# LRFDMDM register map
Vendor: Texas Instruments
Peripheral module from a debugger description file (folder CC27xxx7).
Registers are 32-bit, access per field, reset 0x0 unless marked. A register's access mark holds for its fields unless they carry their own. Offsets are as the file gives them; lines under a group give offsets from that group; [hi:lo] are bit positions; {n}, {i} and the like mark numbered series; 'fields as' and 'values as' point back to an identical list; <NAME> marks a mode.

## LRFDMDM (part 1 of 2)
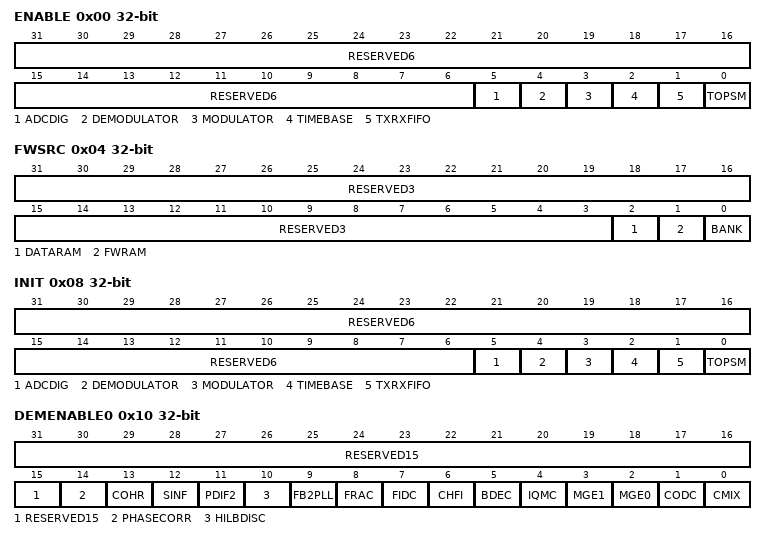
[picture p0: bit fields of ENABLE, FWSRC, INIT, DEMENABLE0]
0x00 ENABLE — Internal. Only to be used through TI provided API.
  [31:6] RESERVED6 ro — Internal. Only to be used through TI provided API.
  [5] ADCDIG rw — Internal. Only to be used through TI provided API.
    1=EN (Internal. Only to be used through TI provided API.); 0=DIS (Internal. Only to be used through TI provided API.)
  [4] DEMODULATOR rw — Internal. Only to be used through TI provided API.
    values as ADCDIG
  [3] MODULATOR rw — Internal. Only to be used through TI provided API.
    values as ADCDIG
  [2] TIMEBASE rw — Internal. Only to be used through TI provided API.
    values as ADCDIG
  [1] TXRXFIFO rw — Internal. Only to be used through TI provided API.
    values as ADCDIG
  [0] TOPSM rw — Internal. Only to be used through TI provided API.
    values as ADCDIG
0x04 FWSRC — Internal. Only to be used through TI provided API.
  [31:3] RESERVED3 ro — Internal. Only to be used through TI provided API.
  [2] DATARAM rw — Internal. Only to be used through TI provided API.
    1=S2RRAM (Internal. Only to be used through TI provided API.); 0=MDMRAM (Internal. Only to be used through TI provided API.)
  [1] FWRAM rw — Internal. Only to be used through TI provided API.
    values as DATARAM
  [0] BANK rw — Internal. Only to be used through TI provided API.
    1=ONE (Internal. Only to be used through TI provided API.); 0=ZERO (Internal. Only to be used through TI provided API.)
0x08 INIT — Internal. Only to be used through TI provided API.
  [31:6] RESERVED6 ro — Internal. Only to be used through TI provided API.
  [5] ADCDIG wo — Internal. Only to be used through TI provided API.
    1=RESET (Internal. Only to be used through TI provided API.); 0=NO_EFFECT (Internal. Only to be used through TI provided API.)
  [4] DEMODULATOR wo — Internal. Only to be used through TI provided API.
    values as ADCDIG
  [3] MODULATOR wo — Internal. Only to be used through TI provided API.
    values as ADCDIG
  [2] TIMEBASE wo — Internal. Only to be used through TI provided API.
    values as ADCDIG
  [1] TXRXFIFO wo — Internal. Only to be used through TI provided API.
    values as ADCDIG
  [0] TOPSM wo — Internal. Only to be used through TI provided API.
    values as ADCDIG
0x10 DEMENABLE0 — Internal. Only to be used through TI provided API.
  [31:15] RESERVED15 ro — Internal. Only to be used through TI provided API.
  [14] PHASECORR rw — Internal. Only to be used through TI provided API.
  [13] COHR rw — Internal. Only to be used through TI provided API.
  [12] SINF rw — Internal. Only to be used through TI provided API.
  [11] PDIF2 rw — Internal. Only to be used through TI provided API.
  [10] HILBDISC rw — Internal. Only to be used through TI provided API.
  [9] FB2PLL rw — Internal. Only to be used through TI provided API.
  [8] FRAC rw — Internal. Only to be used through TI provided API.
    values as ENABLE.ADCDIG
  [7] FIDC rw — Internal. Only to be used through TI provided API.
    values as ENABLE.ADCDIG
  [6] CHFI rw — Internal. Only to be used through TI provided API.
    values as ENABLE.ADCDIG
  [5] BDEC rw — Internal. Only to be used through TI provided API.
    values as ENABLE.ADCDIG
  [4] IQMC rw — Internal. Only to be used through TI provided API.
    values as ENABLE.ADCDIG
  [3] MGE1 rw — Internal. Only to be used through TI provided API.
    values as ENABLE.ADCDIG
  [2] MGE0 rw — Internal. Only to be used through TI provided API.
    values as ENABLE.ADCDIG
  [1] CODC rw — Internal. Only to be used through TI provided API.
    values as ENABLE.ADCDIG
  [0] CMIX rw — Internal. Only to be used through TI provided API.
    values as ENABLE.ADCDIG
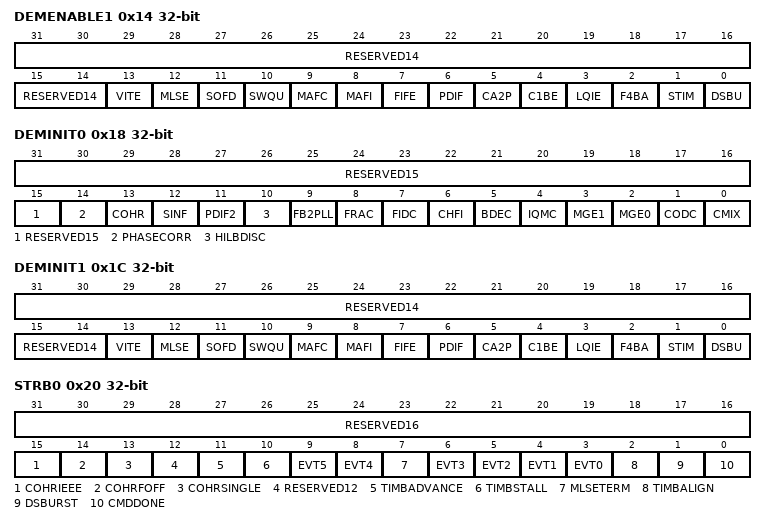
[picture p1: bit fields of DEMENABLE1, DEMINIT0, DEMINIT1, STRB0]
0x14 DEMENABLE1 — Internal. Only to be used through TI provided API.
  [31:14] RESERVED14 ro — Internal. Only to be used through TI provided API.
  [13] VITE rw — Internal. Only to be used through TI provided API.
    values as ENABLE.ADCDIG
  [12] MLSE rw — Internal. Only to be used through TI provided API.
    values as ENABLE.ADCDIG
  [11] SOFD rw — Internal. Only to be used through TI provided API.
    values as ENABLE.ADCDIG
  [10] SWQU rw — Internal. Only to be used through TI provided API.
    values as ENABLE.ADCDIG
  [9] MAFC rw — Internal. Only to be used through TI provided API.
    values as ENABLE.ADCDIG
  [8] MAFI rw — Internal. Only to be used through TI provided API.
    values as ENABLE.ADCDIG
  [7] FIFE rw — Internal. Only to be used through TI provided API.
    values as ENABLE.ADCDIG
  [6] PDIF rw — Internal. Only to be used through TI provided API.
    values as ENABLE.ADCDIG
  [5] CA2P rw — Internal. Only to be used through TI provided API.
    values as ENABLE.ADCDIG
  [4] C1BE rw — Internal. Only to be used through TI provided API.
    values as ENABLE.ADCDIG
  [3] LQIE rw — Internal. Only to be used through TI provided API.
    values as ENABLE.ADCDIG
  [2] F4BA rw — Internal. Only to be used through TI provided API.
    values as ENABLE.ADCDIG
  [1] STIM rw — Internal. Only to be used through TI provided API.
    values as ENABLE.ADCDIG
  [0] DSBU rw — Internal. Only to be used through TI provided API.
    values as ENABLE.ADCDIG
0x18 DEMINIT0 — Internal. Only to be used through TI provided API.
  [31:15] RESERVED15 ro — Internal. Only to be used through TI provided API.
  [14] PHASECORR wo — Internal. Only to be used through TI provided API.
  [13] COHR wo — Internal. Only to be used through TI provided API.
  [12] SINF wo — Internal. Only to be used through TI provided API.
  [11] PDIF2 wo — Internal. Only to be used through TI provided API.
  [10] HILBDISC wo — Internal. Only to be used through TI provided API.
  [9] FB2PLL wo — Internal. Only to be used through TI provided API.
  [8] FRAC wo — Internal. Only to be used through TI provided API.
    values as INIT.ADCDIG
  [7] FIDC wo — Internal. Only to be used through TI provided API.
    values as INIT.ADCDIG
  [6] CHFI wo — Internal. Only to be used through TI provided API.
    values as INIT.ADCDIG
  [5] BDEC wo — Internal. Only to be used through TI provided API.
    values as INIT.ADCDIG
  [4] IQMC wo — Internal. Only to be used through TI provided API.
    values as INIT.ADCDIG
  [3] MGE1 wo — Internal. Only to be used through TI provided API.
    values as INIT.ADCDIG
  [2] MGE0 wo — Internal. Only to be used through TI provided API.
    values as INIT.ADCDIG
  [1] CODC wo — Internal. Only to be used through TI provided API.
    values as INIT.ADCDIG
  [0] CMIX wo — Internal. Only to be used through TI provided API.
    values as INIT.ADCDIG
0x1C DEMINIT1 — Internal. Only to be used through TI provided API.
  [31:14] RESERVED14 ro — Internal. Only to be used through TI provided API.
  [13] VITE wo — Internal. Only to be used through TI provided API.
    values as INIT.ADCDIG
  [12] MLSE wo — Internal. Only to be used through TI provided API.
    values as INIT.ADCDIG
  [11] SOFD wo — Internal. Only to be used through TI provided API.
    values as INIT.ADCDIG
  [10] SWQU wo — Internal. Only to be used through TI provided API.
    values as INIT.ADCDIG
  [9] MAFC wo — Internal. Only to be used through TI provided API.
    values as INIT.ADCDIG
  [8] MAFI wo — Internal. Only to be used through TI provided API.
    values as INIT.ADCDIG
  [7] FIFE wo — Internal. Only to be used through TI provided API.
    values as INIT.ADCDIG
  [6] PDIF wo — Internal. Only to be used through TI provided API.
    values as INIT.ADCDIG
  [5] CA2P wo — Internal. Only to be used through TI provided API.
    values as INIT.ADCDIG
  [4] C1BE wo — Internal. Only to be used through TI provided API.
    values as INIT.ADCDIG
  [3] LQIE wo — Internal. Only to be used through TI provided API.
    values as INIT.ADCDIG
  [2] F4BA wo — Internal. Only to be used through TI provided API.
    values as INIT.ADCDIG
  [1] STIM wo — Internal. Only to be used through TI provided API.
    values as INIT.ADCDIG
  [0] DSBU wo — Internal. Only to be used through TI provided API.
    values as INIT.ADCDIG
0x20 STRB0 — Internal. Only to be used through TI provided API.
  [31:16] RESERVED16 ro — Internal. Only to be used through TI provided API.
  [15] COHRIEEE wo — Internal. Only to be used through TI provided API.
  [14] COHRFOFF wo — Internal. Only to be used through TI provided API.
  [13] COHRSINGLE wo — Internal. Only to be used through TI provided API.
  [12] RESERVED12 ro — Internal. Only to be used through TI provided API.
  [11] TIMBADVANCE wo — Internal. Only to be used through TI provided API.
    1=ON (Internal. Only to be used through TI provided API.); 0=NO_EFFECT (Internal. Only to be used through TI provided API.)
  [10] TIMBSTALL wo — Internal. Only to be used through TI provided API.
    values as TIMBADVANCE
  [9] EVT5 wo — Internal. Only to be used through TI provided API.
    values as FWSRC.BANK
  [8] EVT4 wo — Internal. Only to be used through TI provided API.
    values as FWSRC.BANK
  [7] MLSETERM wo — Internal. Only to be used through TI provided API.
    1=ON (Internal. Only to be used through TI provided API.); 0=OFF (Internal. Only to be used through TI provided API.)
  [n+3] EVT{n} wo (n=0..3) — Internal. Only to be used through TI provided API.
    values as FWSRC.BANK
  [2] TIMBALIGN wo — Internal. Only to be used through TI provided API.
    values as TIMBADVANCE
  [1] DSBURST wo — Internal. Only to be used through TI provided API.
    1=RESTART (Internal. Only to be used through TI provided API.); 0=NO_EFFECT (Internal. Only to be used through TI provided API.)
  [0] CMDDONE wo — Internal. Only to be used through TI provided API.
    1=YES (Internal. Only to be used through TI provided API.); 0=NO (Internal. Only to be used through TI provided API.)
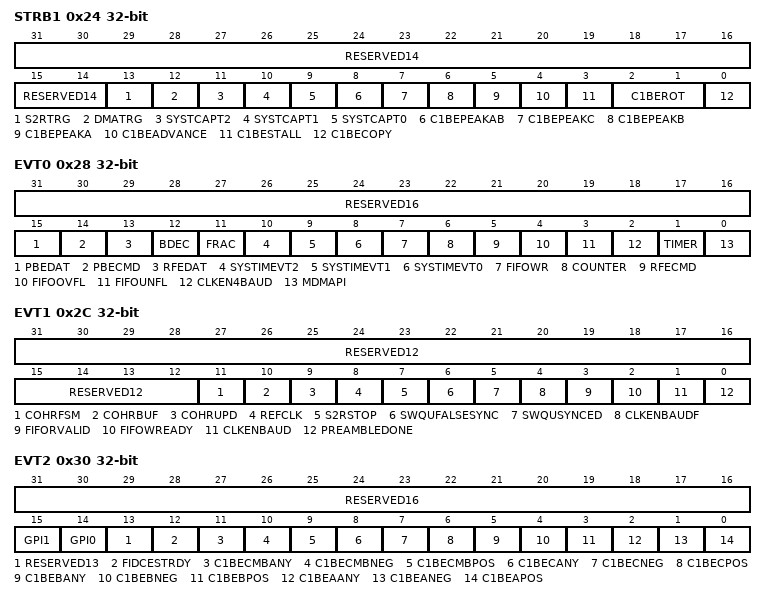
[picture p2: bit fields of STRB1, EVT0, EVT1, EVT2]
0x24 STRB1 — Internal. Only to be used through TI provided API.
  [31:14] RESERVED14 ro — Internal. Only to be used through TI provided API.
  [13] S2RTRG wo — Internal. Only to be used through TI provided API.
    values as FWSRC.BANK
  [12] DMATRG wo — Internal. Only to be used through TI provided API.
    values as FWSRC.BANK
  [11] SYSTCAPT2 wo — Internal. Only to be used through TI provided API.
    values as FWSRC.BANK
  [10] SYSTCAPT1 wo — Internal. Only to be used through TI provided API.
    values as FWSRC.BANK
  [9] SYSTCAPT0 wo — Internal. Only to be used through TI provided API.
    values as FWSRC.BANK
  [8] C1BEPEAKAB wo — Internal. Only to be used through TI provided API.
    values as FWSRC.BANK
  [7] C1BEPEAKC wo — Internal. Only to be used through TI provided API.
    values as FWSRC.BANK
  [6] C1BEPEAKB wo — Internal. Only to be used through TI provided API.
    values as FWSRC.BANK
  [5] C1BEPEAKA wo — Internal. Only to be used through TI provided API.
    values as FWSRC.BANK
  [4] C1BEADVANCE wo — Internal. Only to be used through TI provided API.
    values as FWSRC.BANK
  [3] C1BESTALL wo — Internal. Only to be used through TI provided API.
    values as FWSRC.BANK
  [2:1] C1BEROT wo — Internal. Only to be used through TI provided API.
    3=ROT16R (Internal. Only to be used through TI provided API.); 2=ROT1L (Internal. Only to be used through TI provided API.); 1=ROT1R (Internal. Only to be used through TI provided API.); 0=ROT0 (Internal. Only to be used through TI provided API.)
  [0] C1BECOPY wo — Internal. Only to be used through TI provided API.
    values as FWSRC.BANK
0x28 EVT0 ro — Internal. Only to be used through TI provided API.
  [31:16] RESERVED16 — Internal. Only to be used through TI provided API.
  [15] PBEDAT — Internal. Only to be used through TI provided API.
    values as FWSRC.BANK
  [14] PBECMD — Internal. Only to be used through TI provided API.
    values as FWSRC.BANK
  [13] RFEDAT — Internal. Only to be used through TI provided API.
    values as FWSRC.BANK
  [12] BDEC — Internal. Only to be used through TI provided API.
    values as FWSRC.BANK
  [11] FRAC — Internal. Only to be used through TI provided API.
    values as FWSRC.BANK
  [10] SYSTIMEVT2 — Internal. Only to be used through TI provided API.
    values as FWSRC.BANK
  [9] SYSTIMEVT1 — Internal. Only to be used through TI provided API.
    values as FWSRC.BANK
  [8] SYSTIMEVT0 — Internal. Only to be used through TI provided API.
    values as FWSRC.BANK
  [7] FIFOWR — Internal. Only to be used through TI provided API.
    values as FWSRC.BANK
  [6] COUNTER — Internal. Only to be used through TI provided API.
    values as FWSRC.BANK
  [5] RFECMD — Internal. Only to be used through TI provided API.
    values as FWSRC.BANK
  [4] FIFOOVFL — Internal. Only to be used through TI provided API.
    values as FWSRC.BANK
  [3] FIFOUNFL — Internal. Only to be used through TI provided API.
    values as FWSRC.BANK
  [2] CLKEN4BAUD — Internal. Only to be used through TI provided API.
    values as FWSRC.BANK
  [1] TIMER — Internal. Only to be used through TI provided API.
    values as FWSRC.BANK
  [0] MDMAPI — Internal. Only to be used through TI provided API.
    values as FWSRC.BANK
0x2C EVT1 ro — Internal. Only to be used through TI provided API.
  [31:12] RESERVED12 — Internal. Only to be used through TI provided API.
  [11] COHRFSM — Internal. Only to be used through TI provided API.
  [10] COHRBUF — Internal. Only to be used through TI provided API.
  [9] COHRUPD — Internal. Only to be used through TI provided API.
  [8] REFCLK — Internal. Only to be used through TI provided API.
    values as FWSRC.BANK
  [7] S2RSTOP — Internal. Only to be used through TI provided API.
    values as FWSRC.BANK
  [6] SWQUFALSESYNC — Internal. Only to be used through TI provided API.
    values as FWSRC.BANK
  [5] SWQUSYNCED — Internal. Only to be used through TI provided API.
    values as FWSRC.BANK
  [4] CLKENBAUDF — Internal. Only to be used through TI provided API.
    values as FWSRC.BANK
  [3] FIFORVALID — Internal. Only to be used through TI provided API.
    values as FWSRC.BANK
  [2] FIFOWREADY — Internal. Only to be used through TI provided API.
    values as FWSRC.BANK
  [1] CLKENBAUD — Internal. Only to be used through TI provided API.
    values as FWSRC.BANK
  [0] PREAMBLEDONE — Internal. Only to be used through TI provided API.
    values as FWSRC.BANK
0x30 EVT2 ro — Internal. Only to be used through TI provided API.
  [31:16] RESERVED16 — Internal. Only to be used through TI provided API.
  [15] GPI1 — Internal. Only to be used through TI provided API.
    values as FWSRC.BANK
  [14] GPI0 — Internal. Only to be used through TI provided API.
    values as FWSRC.BANK
  [13] RESERVED13 — Internal. Only to be used through TI provided API.
  [12] FIDCESTRDY — Internal. Only to be used through TI provided API.
    values as FWSRC.BANK
  [11] C1BECMBANY — Internal. Only to be used through TI provided API.
    values as FWSRC.BANK
  [10] C1BECMBNEG — Internal. Only to be used through TI provided API.
    values as FWSRC.BANK
  [9] C1BECMBPOS — Internal. Only to be used through TI provided API.
    values as FWSRC.BANK
  [8] C1BECANY — Internal. Only to be used through TI provided API.
    values as FWSRC.BANK
  [7] C1BECNEG — Internal. Only to be used through TI provided API.
    values as FWSRC.BANK
  [6] C1BECPOS — Internal. Only to be used through TI provided API.
    values as FWSRC.BANK
  [5] C1BEBANY — Internal. Only to be used through TI provided API.
    values as FWSRC.BANK
  [4] C1BEBNEG — Internal. Only to be used through TI provided API.
    values as FWSRC.BANK
  [3] C1BEBPOS — Internal. Only to be used through TI provided API.
    values as FWSRC.BANK
  [2] C1BEAANY — Internal. Only to be used through TI provided API.
    values as FWSRC.BANK
  [1] C1BEANEG — Internal. Only to be used through TI provided API.
    values as FWSRC.BANK
  [0] C1BEAPOS — Internal. Only to be used through TI provided API.
    values as FWSRC.BANK
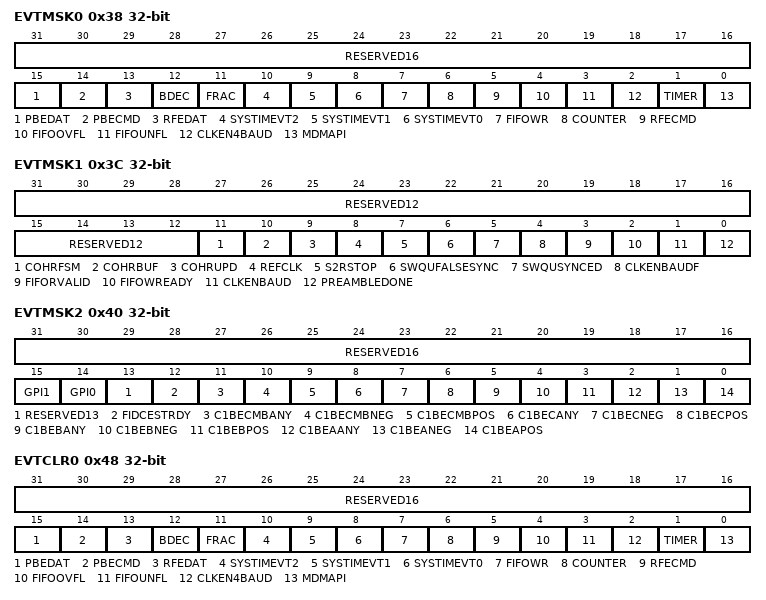
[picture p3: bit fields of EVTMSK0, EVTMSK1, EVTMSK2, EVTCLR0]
0x38 EVTMSK0 — Internal. Only to be used through TI provided API.
  [31:16] RESERVED16 ro — Internal. Only to be used through TI provided API.
  [15] PBEDAT rw — Internal. Only to be used through TI provided API.
    values as ENABLE.ADCDIG
  [14] PBECMD rw — Internal. Only to be used through TI provided API.
    values as ENABLE.ADCDIG
  [13] RFEDAT rw — Internal. Only to be used through TI provided API.
    values as ENABLE.ADCDIG
  [12] BDEC rw — Internal. Only to be used through TI provided API.
    values as ENABLE.ADCDIG
  [11] FRAC rw — Internal. Only to be used through TI provided API.
    values as ENABLE.ADCDIG
  [10] SYSTIMEVT2 rw — Internal. Only to be used through TI provided API.
    values as ENABLE.ADCDIG
  [9] SYSTIMEVT1 rw — Internal. Only to be used through TI provided API.
    values as ENABLE.ADCDIG
  [8] SYSTIMEVT0 rw — Internal. Only to be used through TI provided API.
    values as ENABLE.ADCDIG
  [7] FIFOWR rw — Internal. Only to be used through TI provided API.
    values as ENABLE.ADCDIG
  [6] COUNTER rw — Internal. Only to be used through TI provided API.
    values as ENABLE.ADCDIG
  [5] RFECMD rw — Internal. Only to be used through TI provided API.
    values as ENABLE.ADCDIG
  [4] FIFOOVFL rw — Internal. Only to be used through TI provided API.
    values as ENABLE.ADCDIG
  [3] FIFOUNFL rw — Internal. Only to be used through TI provided API.
    values as ENABLE.ADCDIG
  [2] CLKEN4BAUD rw — Internal. Only to be used through TI provided API.
    values as ENABLE.ADCDIG
  [1] TIMER rw — Internal. Only to be used through TI provided API.
    values as ENABLE.ADCDIG
  [0] MDMAPI rw — Internal. Only to be used through TI provided API.
    values as ENABLE.ADCDIG
0x3C EVTMSK1 — Internal. Only to be used through TI provided API.
  [31:12] RESERVED12 ro — Internal. Only to be used through TI provided API.
  [11] COHRFSM rw — Internal. Only to be used through TI provided API.
  [10] COHRBUF rw — Internal. Only to be used through TI provided API.
  [9] COHRUPD rw — Internal. Only to be used through TI provided API.
  [8] REFCLK rw — Internal. Only to be used through TI provided API.
    values as ENABLE.ADCDIG
  [7] S2RSTOP rw — Internal. Only to be used through TI provided API.
    values as ENABLE.ADCDIG
  [6] SWQUFALSESYNC rw — Internal. Only to be used through TI provided API.
    values as ENABLE.ADCDIG
  [5] SWQUSYNCED rw — Internal. Only to be used through TI provided API.
    values as ENABLE.ADCDIG
  [4] CLKENBAUDF rw — Internal. Only to be used through TI provided API.
    values as ENABLE.ADCDIG
  [3] FIFORVALID rw — Internal. Only to be used through TI provided API.
    values as ENABLE.ADCDIG
  [2] FIFOWREADY rw — Internal. Only to be used through TI provided API.
    values as ENABLE.ADCDIG
  [1] CLKENBAUD rw — Internal. Only to be used through TI provided API.
    values as ENABLE.ADCDIG
  [0] PREAMBLEDONE rw — Internal. Only to be used through TI provided API.
    values as ENABLE.ADCDIG
0x40 EVTMSK2 — Internal. Only to be used through TI provided API.
  [31:16] RESERVED16 ro — Internal. Only to be used through TI provided API.
  [15] GPI1 rw — Internal. Only to be used through TI provided API.
    values as ENABLE.ADCDIG
  [14] GPI0 rw — Internal. Only to be used through TI provided API.
    values as ENABLE.ADCDIG
  [13] RESERVED13 ro — Internal. Only to be used through TI provided API.
  [12] FIDCESTRDY rw — Internal. Only to be used through TI provided API.
    values as ENABLE.ADCDIG
  [11] C1BECMBANY rw — Internal. Only to be used through TI provided API.
    values as ENABLE.ADCDIG
  [10] C1BECMBNEG rw — Internal. Only to be used through TI provided API.
    values as ENABLE.ADCDIG
  [9] C1BECMBPOS rw — Internal. Only to be used through TI provided API.
    values as ENABLE.ADCDIG
  [8] C1BECANY rw — Internal. Only to be used through TI provided API.
    values as ENABLE.ADCDIG
  [7] C1BECNEG rw — Internal. Only to be used through TI provided API.
    values as ENABLE.ADCDIG
  [6] C1BECPOS rw — Internal. Only to be used through TI provided API.
    values as ENABLE.ADCDIG
  [5] C1BEBANY rw — Internal. Only to be used through TI provided API.
    values as ENABLE.ADCDIG
  [4] C1BEBNEG rw — Internal. Only to be used through TI provided API.
    values as ENABLE.ADCDIG
  [3] C1BEBPOS rw — Internal. Only to be used through TI provided API.
    values as ENABLE.ADCDIG
  [2] C1BEAANY rw — Internal. Only to be used through TI provided API.
    values as ENABLE.ADCDIG
  [1] C1BEANEG rw — Internal. Only to be used through TI provided API.
    values as ENABLE.ADCDIG
  [0] C1BEAPOS rw — Internal. Only to be used through TI provided API.
    values as ENABLE.ADCDIG
0x48 EVTCLR0 — Internal. Only to be used through TI provided API.
  [31:16] RESERVED16 ro — Internal. Only to be used through TI provided API.
  [15] PBEDAT wo — Internal. Only to be used through TI provided API.
    1=CLEAR (Internal. Only to be used through TI provided API.); 0=RETAIN (Internal. Only to be used through TI provided API.)
  [14] PBECMD wo — Internal. Only to be used through TI provided API.
    values as PBEDAT
  [13] RFEDAT wo — Internal. Only to be used through TI provided API.
    values as PBEDAT
  [12] BDEC wo — Internal. Only to be used through TI provided API.
    values as PBEDAT
  [11] FRAC wo — Internal. Only to be used through TI provided API.
    values as PBEDAT
  [10] SYSTIMEVT2 wo — Internal. Only to be used through TI provided API.
    values as PBEDAT
  [9] SYSTIMEVT1 wo — Internal. Only to be used through TI provided API.
    values as PBEDAT
  [8] SYSTIMEVT0 wo — Internal. Only to be used through TI provided API.
    values as PBEDAT
  [7] FIFOWR wo — Internal. Only to be used through TI provided API.
    values as PBEDAT
  [6] COUNTER wo — Internal. Only to be used through TI provided API.
    values as PBEDAT
  [5] RFECMD wo — Internal. Only to be used through TI provided API.
    values as PBEDAT
  [4] FIFOOVFL wo — Internal. Only to be used through TI provided API.
    values as PBEDAT
  [3] FIFOUNFL wo — Internal. Only to be used through TI provided API.
    values as PBEDAT
  [2] CLKEN4BAUD wo — Internal. Only to be used through TI provided API.
    values as PBEDAT
  [1] TIMER wo — Internal. Only to be used through TI provided API.
    values as PBEDAT
  [0] MDMAPI wo — Internal. Only to be used through TI provided API.
    values as PBEDAT
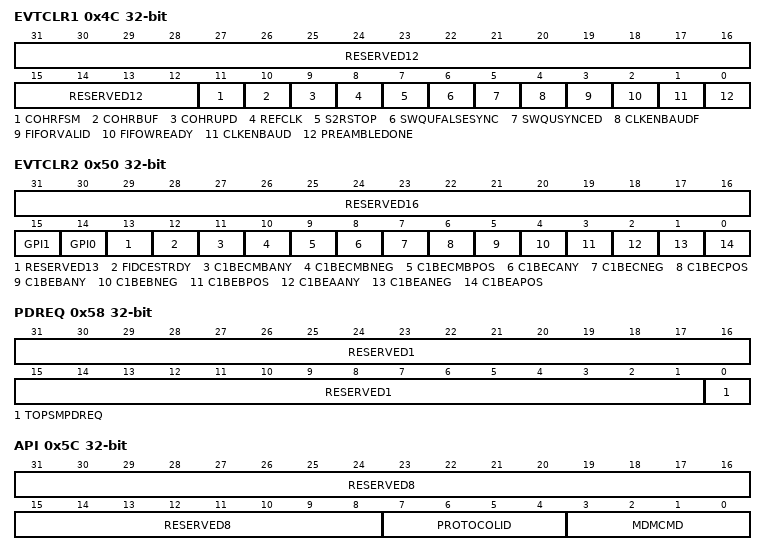
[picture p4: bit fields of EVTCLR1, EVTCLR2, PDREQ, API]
0x4C EVTCLR1 — Internal. Only to be used through TI provided API.
  [31:12] RESERVED12 ro — Internal. Only to be used through TI provided API.
  [11] COHRFSM wo — Internal. Only to be used through TI provided API.
  [10] COHRBUF wo — Internal. Only to be used through TI provided API.
  [9] COHRUPD wo — Internal. Only to be used through TI provided API.
  [8] REFCLK wo — Internal. Only to be used through TI provided API.
    values as EVTCLR0.PBEDAT
  [7] S2RSTOP wo — Internal. Only to be used through TI provided API.
    values as EVTCLR0.PBEDAT
  [6] SWQUFALSESYNC wo — Internal. Only to be used through TI provided API.
    values as EVTCLR0.PBEDAT
  [5] SWQUSYNCED wo — Internal. Only to be used through TI provided API.
    values as EVTCLR0.PBEDAT
  [4] CLKENBAUDF wo — Internal. Only to be used through TI provided API.
    values as EVTCLR0.PBEDAT
  [3] FIFORVALID wo — Internal. Only to be used through TI provided API.
    values as EVTCLR0.PBEDAT
  [2] FIFOWREADY wo — Internal. Only to be used through TI provided API.
    values as EVTCLR0.PBEDAT
  [1] CLKENBAUD wo — Internal. Only to be used through TI provided API.
    values as EVTCLR0.PBEDAT
  [0] PREAMBLEDONE wo — Internal. Only to be used through TI provided API.
    values as EVTCLR0.PBEDAT
0x50 EVTCLR2 — Internal. Only to be used through TI provided API.
  [31:16] RESERVED16 ro — Internal. Only to be used through TI provided API.
  [15] GPI1 wo — Internal. Only to be used through TI provided API.
    values as EVTCLR0.PBEDAT
  [14] GPI0 wo — Internal. Only to be used through TI provided API.
    values as EVTCLR0.PBEDAT
  [13] RESERVED13 ro — Internal. Only to be used through TI provided API.
  [12] FIDCESTRDY wo — Internal. Only to be used through TI provided API.
    values as EVTCLR0.PBEDAT
  [11] C1BECMBANY wo — Internal. Only to be used through TI provided API.
    values as EVTCLR0.PBEDAT
  [10] C1BECMBNEG wo — Internal. Only to be used through TI provided API.
    values as EVTCLR0.PBEDAT
  [9] C1BECMBPOS wo — Internal. Only to be used through TI provided API.
    values as EVTCLR0.PBEDAT
  [8] C1BECANY wo — Internal. Only to be used through TI provided API.
    values as EVTCLR0.PBEDAT
  [7] C1BECNEG wo — Internal. Only to be used through TI provided API.
    values as EVTCLR0.PBEDAT
  [6] C1BECPOS wo — Internal. Only to be used through TI provided API.
    values as EVTCLR0.PBEDAT
  [5] C1BEBANY wo — Internal. Only to be used through TI provided API.
    values as EVTCLR0.PBEDAT
  [4] C1BEBNEG wo — Internal. Only to be used through TI provided API.
    values as EVTCLR0.PBEDAT
  [3] C1BEBPOS wo — Internal. Only to be used through TI provided API.
    values as EVTCLR0.PBEDAT
  [2] C1BEAANY wo — Internal. Only to be used through TI provided API.
    values as EVTCLR0.PBEDAT
  [1] C1BEANEG wo — Internal. Only to be used through TI provided API.
    values as EVTCLR0.PBEDAT
  [0] C1BEAPOS wo — Internal. Only to be used through TI provided API.
    values as EVTCLR0.PBEDAT
0x58 PDREQ — Internal. Only to be used through TI provided API.
  [31:1] RESERVED1 ro — Internal. Only to be used through TI provided API.
  [0] TOPSMPDREQ rw — Internal. Only to be used through TI provided API.
    values as STRB0.MLSETERM
0x5C API ro — Internal. Only to be used through TI provided API.
  [31:8] RESERVED8 — Internal. Only to be used through TI provided API.
  [7:4] PROTOCOLID — Internal. Only to be used through TI provided API.
    15=ALLONES (Internal. Only to be used through TI provided API.); 0=ALLZEROS (Internal. Only to be used through TI provided API.)
  [3:0] MDMCMD — Internal. Only to be used through TI provided API.
    values as PROTOCOLID
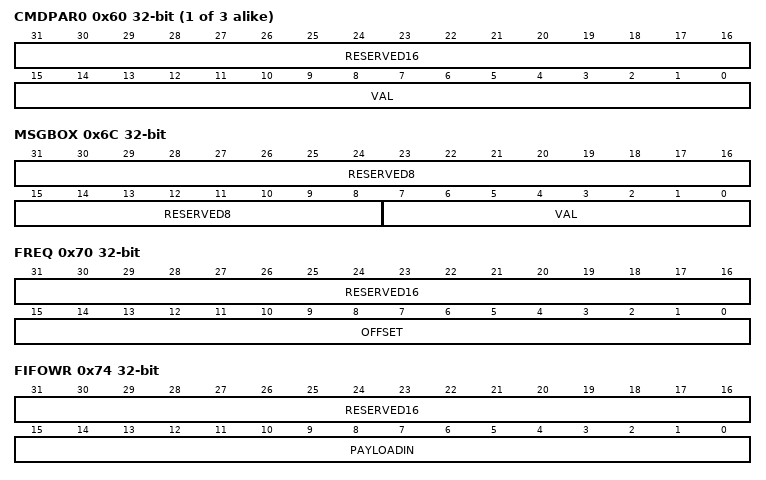
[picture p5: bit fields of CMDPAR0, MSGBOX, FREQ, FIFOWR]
{0x60+4i} CMDPAR{i} ro (i=0..2) — Internal. Only to be used through TI provided API.
  [31:16] RESERVED16 — Internal. Only to be used through TI provided API.
  [15:0] VAL — Internal. Only to be used through TI provided API.
    0xFFFF=ALLONES (Internal. Only to be used through TI provided API.); 0=ALLZEROS (Internal. Only to be used through TI provided API.)
0x6C MSGBOX — Internal. Only to be used through TI provided API.
  [31:8] RESERVED8 ro — Internal. Only to be used through TI provided API.
  [7:0] VAL rw — Internal. Only to be used through TI provided API.
    255=ALLONES (Internal. Only to be used through TI provided API.); 0=ALLZEROS (Internal. Only to be used through TI provided API.)
0x70 FREQ — Internal. Only to be used through TI provided API.
  [31:16] RESERVED16 ro — Internal. Only to be used through TI provided API.
  [15:0] OFFSET rw — Internal. Only to be used through TI provided API.
    values as CMDPAR0.VAL
0x74 FIFOWR — Internal. Only to be used through TI provided API.
  [31:16] RESERVED16 ro — Internal. Only to be used through TI provided API.
  [15:0] PAYLOADIN rw — Internal. Only to be used through TI provided API.
    values as CMDPAR0.VAL
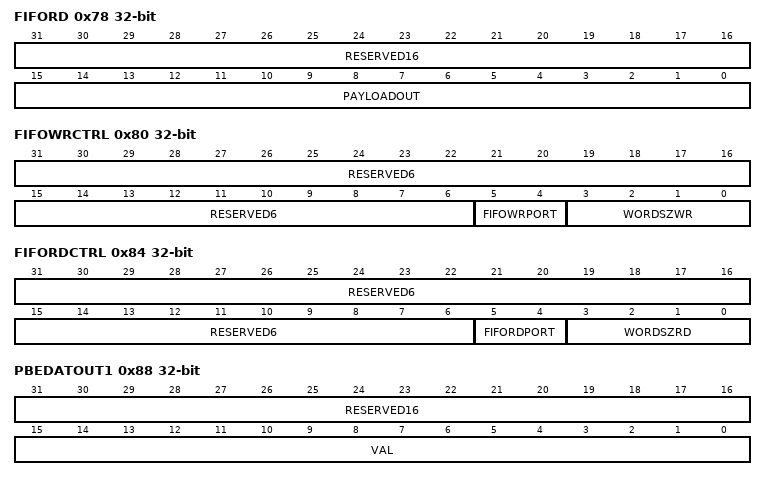
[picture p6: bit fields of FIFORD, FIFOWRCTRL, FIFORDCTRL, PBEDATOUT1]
0x78 FIFORD ro — Internal. Only to be used through TI provided API.
  [31:16] RESERVED16 — Internal. Only to be used through TI provided API.
  [15:0] PAYLOADOUT — Internal. Only to be used through TI provided API.
    values as CMDPAR0.VAL
0x80 FIFOWRCTRL — Internal. Only to be used through TI provided API.
  [31:6] RESERVED6 ro — Internal. Only to be used through TI provided API.
  [5:4] FIFOWRPORT rw — Internal. Only to be used through TI provided API.
    2=PBE (Internal. Only to be used through TI provided API.); 1=MODEM (Internal. Only to be used through TI provided API.); 0=MDMFIFOWR (Internal. Only to be used through TI provided API.)
  [3:0] WORDSZWR rw — Internal. Only to be used through TI provided API.
    {v}=BITS{v+1} (Internal. Only to be used through TI provided API.) (v=0..15)
0x84 FIFORDCTRL — Internal. Only to be used through TI provided API.
  [31:6] RESERVED6 ro — Internal. Only to be used through TI provided API.
  [5:4] FIFORDPORT rw — Internal. Only to be used through TI provided API.
    2=PBE (Internal. Only to be used through TI provided API.); 1=MODEM (Internal. Only to be used through TI provided API.); 0=MDMFIFORD (Internal. Only to be used through TI provided API.)
  [3:0] WORDSZRD rw — Internal. Only to be used through TI provided API.
    values as FIFOWRCTRL.WORDSZWR
0x88 PBEDATOUT1 — Internal. Only to be used through TI provided API.
  [31:16] RESERVED16 ro — Internal. Only to be used through TI provided API.
  [15:0] VAL rw — Internal. Only to be used through TI provided API.
    values as CMDPAR0.VAL
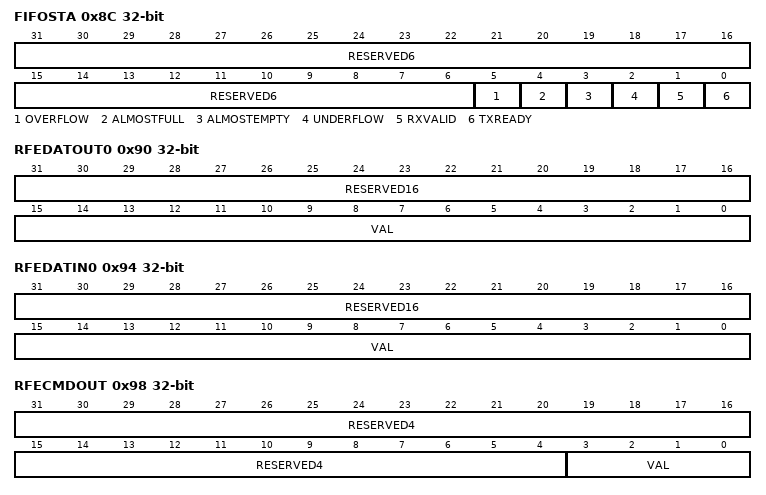
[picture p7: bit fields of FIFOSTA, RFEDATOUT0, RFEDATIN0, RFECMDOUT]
0x8C FIFOSTA ro — Internal. Only to be used through TI provided API.
  [31:6] RESERVED6 — Internal. Only to be used through TI provided API.
  [5] OVERFLOW — Internal. Only to be used through TI provided API.
    values as FWSRC.BANK
  [4] ALMOSTFULL — Internal. Only to be used through TI provided API.
    values as FWSRC.BANK
  [3] ALMOSTEMPTY — Internal. Only to be used through TI provided API.
    values as FWSRC.BANK
  [2] UNDERFLOW — Internal. Only to be used through TI provided API.
    values as FWSRC.BANK
  [1] RXVALID — Internal. Only to be used through TI provided API.
    values as FWSRC.BANK
  [0] TXREADY — Internal. Only to be used through TI provided API.
    values as FWSRC.BANK
0x90 RFEDATOUT0 — Internal. Only to be used through TI provided API.
  fields as PBEDATOUT1
0x94 RFEDATIN0 ro — Internal. Only to be used through TI provided API.
  fields as CMDPAR0
0x98 RFECMDOUT — Internal. Only to be used through TI provided API.
  [31:4] RESERVED4 ro — Internal. Only to be used through TI provided API.
  [3:0] VAL rw — Internal. Only to be used through TI provided API.
    values as API.PROTOCOLID
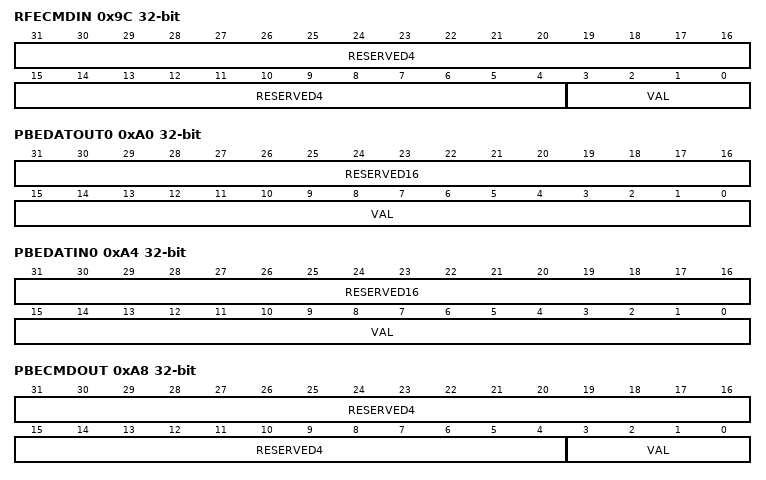
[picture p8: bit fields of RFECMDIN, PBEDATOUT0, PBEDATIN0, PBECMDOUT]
0x9C RFECMDIN ro — Internal. Only to be used through TI provided API.
  [31:4] RESERVED4 — Internal. Only to be used through TI provided API.
  [3:0] VAL — Internal. Only to be used through TI provided API.
    values as API.PROTOCOLID
0xA0 PBEDATOUT0 — Internal. Only to be used through TI provided API.
  fields as PBEDATOUT1
0xA4 PBEDATIN0 ro — Internal. Only to be used through TI provided API.
  fields as CMDPAR0
0xA8 PBECMDOUT — Internal. Only to be used through TI provided API.
  fields as RFECMDOUT
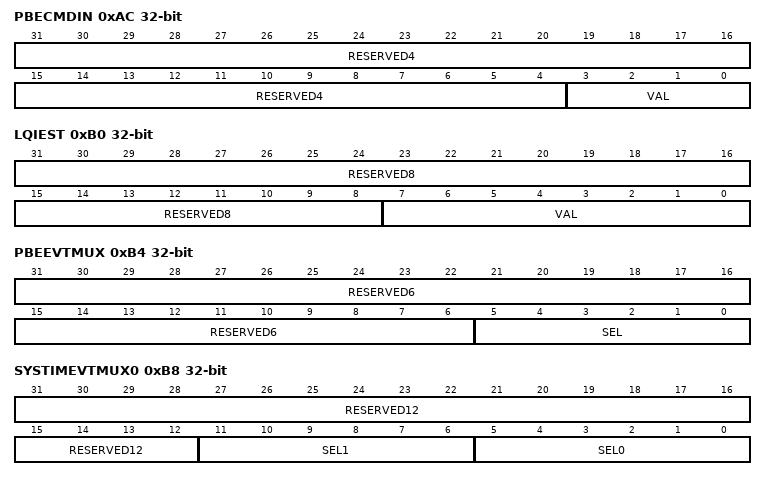
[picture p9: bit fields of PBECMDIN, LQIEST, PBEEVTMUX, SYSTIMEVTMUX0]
0xAC PBECMDIN ro — Internal. Only to be used through TI provided API.
  fields as RFECMDIN
0xB0 LQIEST — Internal. Only to be used through TI provided API.
  fields as MSGBOX
0xB4 PBEEVTMUX — Internal. Only to be used through TI provided API.
  [31:6] RESERVED6 ro — Internal. Only to be used through TI provided API.
  [5:0] SEL rw — Internal. Only to be used through TI provided API.
    63=ALLONES (Internal. Only to be used through TI provided API.); 0=ALLZEROS (Internal. Only to be used through TI provided API.)
0xB8 SYSTIMEVTMUX0 — Internal. Only to be used through TI provided API.
  [31:12] RESERVED12 ro — Internal. Only to be used through TI provided API.
  [11:6] SEL1 rw — Internal. Only to be used through TI provided API.
    values as PBEEVTMUX.SEL
  [5:0] SEL0 rw — Internal. Only to be used through TI provided API.
    values as PBEEVTMUX.SEL
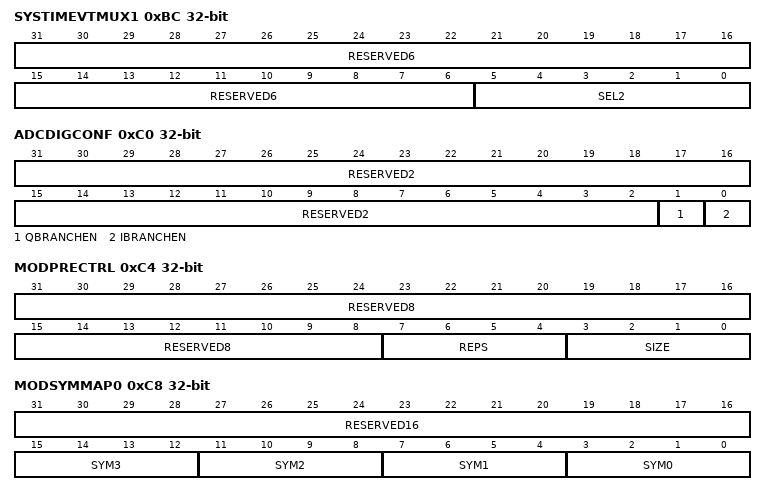
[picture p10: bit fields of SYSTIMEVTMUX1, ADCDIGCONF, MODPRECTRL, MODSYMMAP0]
0xBC SYSTIMEVTMUX1 — Internal. Only to be used through TI provided API.
  [31:6] RESERVED6 ro — Internal. Only to be used through TI provided API.
  [5:0] SEL2 rw — Internal. Only to be used through TI provided API.
    values as PBEEVTMUX.SEL
0xC0 ADCDIGCONF — Internal. Only to be used through TI provided API.
  [31:2] RESERVED2 ro — Internal. Only to be used through TI provided API.
  [1] QBRANCHEN rw — Internal. Only to be used through TI provided API.
    values as STRB0.MLSETERM
  [0] IBRANCHEN rw — Internal. Only to be used through TI provided API.
    values as STRB0.MLSETERM
0xC4 MODPRECTRL — Internal. Only to be used through TI provided API.
  [31:8] RESERVED8 ro — Internal. Only to be used through TI provided API.
  [7:4] REPS rw — Internal. Only to be used through TI provided API.
    {v}=Internal. Only to be used through TI provided API. (v=0..15)
  [3:0] SIZE rw — Internal. Only to be used through TI provided API.
    15=BITS16 (Internal. Only to be used through TI provided API.); 7=BITS8 (Internal. Only to be used through TI provided API.); 3=BITS4 (Internal. Only to be used through TI provided API.)
0xC8 MODSYMMAP0 — Internal. Only to be used through TI provided API.
  [31:16] RESERVED16 ro — Internal. Only to be used through TI provided API.
  [4n+3:4n] SYM{n} rw (n=0..3) — Internal. Only to be used through TI provided API.
    values as API.PROTOCOLID
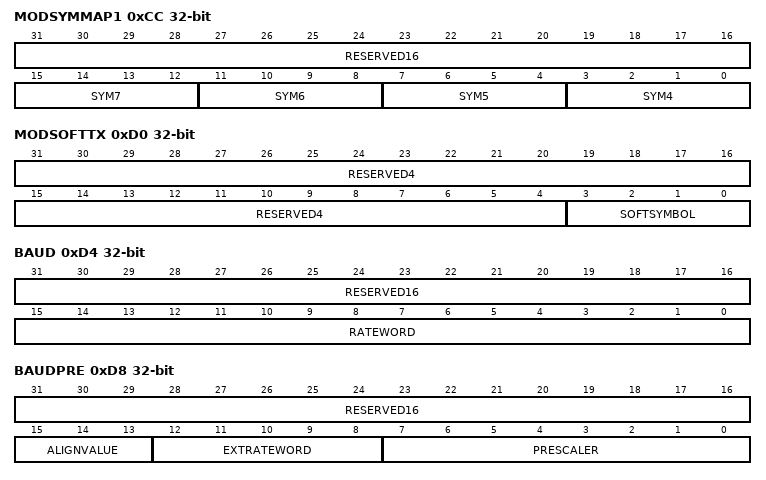
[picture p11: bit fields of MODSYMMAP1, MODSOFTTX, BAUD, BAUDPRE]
0xCC MODSYMMAP1 — Internal. Only to be used through TI provided API.
  [31:16] RESERVED16 ro — Internal. Only to be used through TI provided API.
  [4n-13:4n-16] SYM{n} rw (n=4..7) — Internal. Only to be used through TI provided API.
    values as API.PROTOCOLID
0xD0 MODSOFTTX — Internal. Only to be used through TI provided API.
  [31:4] RESERVED4 ro — Internal. Only to be used through TI provided API.
  [3:0] SOFTSYMBOL rw — Internal. Only to be used through TI provided API.
    values as API.PROTOCOLID
0xD4 BAUD — Internal. Only to be used through TI provided API.
  [31:16] RESERVED16 ro — Internal. Only to be used through TI provided API.
  [15:0] RATEWORD rw — Internal. Only to be used through TI provided API.
    values as CMDPAR0.VAL
0xD8 BAUDPRE — Internal. Only to be used through TI provided API.
  [31:16] RESERVED16 ro — Internal. Only to be used through TI provided API.
  [15:13] ALIGNVALUE rw — Internal. Only to be used through TI provided API.
    7=ALLONES (Internal. Only to be used through TI provided API.); 0=ALLZEROS (Internal. Only to be used through TI provided API.)
  [12:8] EXTRATEWORD rw — Internal. Only to be used through TI provided API.
    31=ALLONES (Internal. Only to be used through TI provided API.); 0=ALLZEROS (Internal. Only to be used through TI provided API.)
  [7:0] PRESCALER rw — Internal. Only to be used through TI provided API.
    values as MSGBOX.VAL
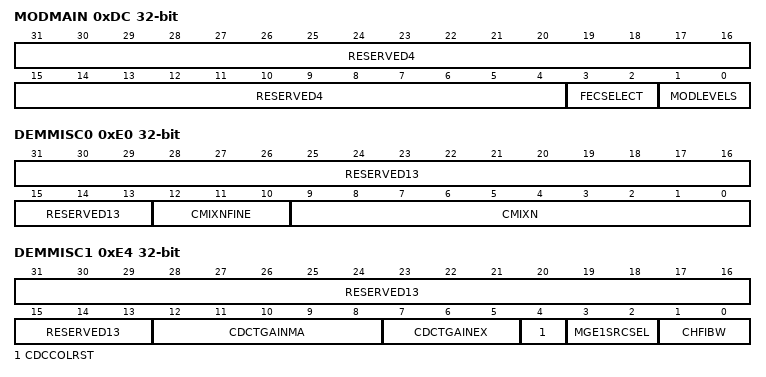
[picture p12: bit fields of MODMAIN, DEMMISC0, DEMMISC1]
0xDC MODMAIN — Internal. Only to be used through TI provided API.
  [31:4] RESERVED4 ro — Internal. Only to be used through TI provided API.
  [3:2] FECSELECT rw — Internal. Only to be used through TI provided API.
    3=BLR (Internal. Only to be used through TI provided API.); 2=RESERVED (Internal. Only to be used through TI provided API.); 1=IEEE15_4 (Internal. Only to be used through TI provided API.); 0=NOSEL (Internal. Only to be used through TI provided API.)
  [1:0] MODLEVELS rw — Internal. Only to be used through TI provided API.
    2=LVL8 (Internal. Only to be used through TI provided API.); 1=LVL4 (Internal. Only to be used through TI provided API.); 0=LVL2 (Internal. Only to be used through TI provided API.)
0xE0 DEMMISC0 — Internal. Only to be used through TI provided API.
  [31:13] RESERVED13 ro — Internal. Only to be used through TI provided API.
  [12:10] CMIXNFINE rw — Internal. Only to be used through TI provided API.
  [9:0] CMIXN rw — Internal. Only to be used through TI provided API.
    0x3FF=ALLONES (Internal. Only to be used through TI provided API.); 0=ALLZEROS (Internal. Only to be used through TI provided API.)
0xE4 DEMMISC1 — Internal. Only to be used through TI provided API.
  [31:13] RESERVED13 ro — Internal. Only to be used through TI provided API.
  [12:8] CDCTGAINMA rw — Internal. Only to be used through TI provided API.
    values as BAUDPRE.EXTRATEWORD
  [7:5] CDCTGAINEX rw — Internal. Only to be used through TI provided API.
    values as BAUDPRE.ALIGNVALUE
  [4] CDCCOLRST rw — Internal. Only to be used through TI provided API.
    values as ENABLE.ADCDIG
  [3:2] MGE1SRCSEL rw — Internal. Only to be used through TI provided API.
    2=CHFI (Internal. Only to be used through TI provided API.); 1=FEXB1 (Internal. Only to be used through TI provided API.); 0=FIDC (Internal. Only to be used through TI provided API.)
  [1:0] CHFIBW rw — Internal. Only to be used through TI provided API.
    3=BW0_29 (Internal. Only to be used through TI provided API.); 2=BW0_41667 (Internal. Only to be used through TI provided API.); 1=BW0_3333 (Internal. Only to be used through TI provided API.); 0=BW0_5 (Internal. Only to be used through TI provided API.)
